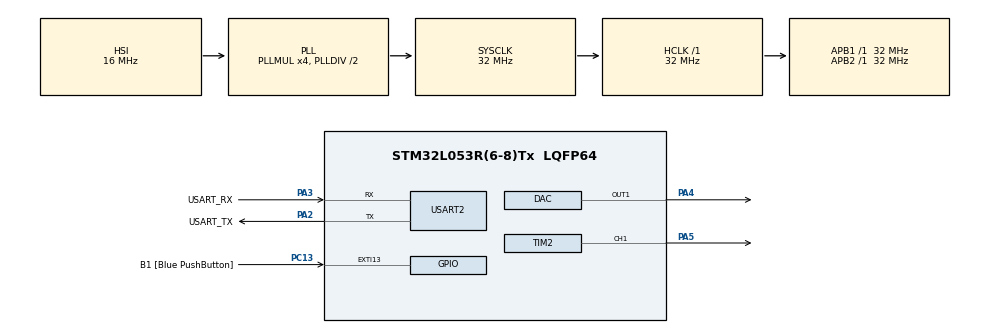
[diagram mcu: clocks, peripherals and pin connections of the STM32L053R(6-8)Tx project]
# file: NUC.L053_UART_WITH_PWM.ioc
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Mcu.Family=STM32L0
Mcu.Name=STM32L053R(6-8)Tx
Mcu.Package=LQFP64
NVIC.USART2_IRQn=true\:0\:0\:false\:false\:true\:true\:true\:true
PA13.GPIO_Label=TMS
PA13.Signal=SYS_SWDIO
PA14.GPIO_Label=TCK
PA14.Signal=SYS_SWCLK
PA2.GPIO_Label=USART_TX
PA2.Mode=Asynchronous
PA2.Signal=USART2_TX
PA3.GPIO_Label=USART_RX
PA3.Mode=Asynchronous
PA3.Signal=USART2_RX
PA4.Signal=COMP_DAC1_group
PA5.Signal=S_TIM2_CH1
PC13.GPIO_Label=B1 [Blue PushButton]
PC13.GPIO_ModeDefaultEXTI=GPIO_MODE_IT_FALLING
PC13.Signal=GPXTI13
PC14-OSC32_IN.Signal=RCC_OSC32_IN
PC15-OSC32_OUT.Signal=RCC_OSC32_OUT
PH0-OSC_IN.Signal=RCC_OSC_IN
PH1-OSC_OUT.Signal=RCC_OSC_OUT
ProjectManager.HeapSize=0x200
ProjectManager.StackSize=0x400
ProjectManager.TargetToolchain=STM32CubeIDE
RCC.AHBFreq_Value=32000000
RCC.APB1Freq_Value=32000000
RCC.APB1TimFreq_Value=32000000
RCC.APB2Freq_Value=32000000
RCC.APB2TimFreq_Value=32000000
RCC.HCLKFreq_Value=32000000
RCC.HSE_VALUE=8000000
RCC.HSI16_VALUE=16000000
RCC.HSI48_VALUE=48000000
RCC.HSI_VALUE=16000000
RCC.LSEState=RCC_LSE_ON
RCC.LSE_VALUE=32768
RCC.MSI_VALUE=2097000
RCC.PLLMUL=RCC_PLLMUL_4
RCC.SYSCLKFreq_VALUE=32000000
RCC.SYSCLKSource=RCC_SYSCLKSOURCE_PLLCLK
RCC.VCOOutputFreq_Value=64000000
SH.COMP_DAC1_group.0=DAC_OUT1,DAC_OUT1
SH.S_TIM2_CH1.0=TIM2_CH1,PWM Generation1 CH1
TIM2.Channel-PWM\ Generation1\ CH1=TIM_CHANNEL_1
TIM2.Period=1500
TIM2.Prescaler=15999
USART2.VirtualMode-Asynchronous=VM_ASYNC
board=NUCLEO-L053R8

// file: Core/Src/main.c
/* USER CODE BEGIN Header */
/**
  ******************************************************************************
  * @file           : main.c
  * @brief          : Main program body
  ******************************************************************************
  * @attention
  *
  * Copyright (c) 2023 STMicroelectronics.
  * All rights reserved.
  *
  * This software is licensed under terms that can be found in the LICENSE file
  * in the root directory of this software component.
  * If no LICENSE file comes with this software, it is provided AS-IS.
  *
  ******************************************************************************
  */
/* USER CODE END Header */
#include "main.h"

DAC_HandleTypeDef hdac;

TIM_HandleTypeDef htim2;

UART_HandleTypeDef huart2;

/* USER CODE BEGIN PV */
volatile uint32_t x=0;
uint8_t Receive_Data[10]={0};
uint32_t i=0;
/* USER CODE END PV */

void SystemClock_Config(void);
static void MX_GPIO_Init(void);
static void MX_USART2_UART_Init(void);
static void MX_DAC_Init(void);
static void MX_TIM2_Init(void);
/* USER CODE BEGIN PFP */
void HAL_UART_RxCpltCallback(UART_HandleTypeDef *huart)
{
	x = (100*Receive_Data[0]);
	i=10+i;

  memset(Receive_Data, '\0',10);
  HAL_UART_Receive_IT(&huart2, Receive_Data , 1);

}
/* USER CODE END PFP */

int main(void)
{

  /* MCU Configuration--------------------------------------------------------*/

  /* Reset of all peripherals, Initializes the Flash interface and the Systick. */
  HAL_Init();

  /* Configure the system clock */
  SystemClock_Config();

  /* Initialize all configured peripherals */
  MX_GPIO_Init();
  MX_USART2_UART_Init();
  MX_DAC_Init();
  MX_TIM2_Init();
  /* USER CODE BEGIN 2 */
  HAL_TIM_PWM_Start(&htim2, TIM_CHANNEL_1);
  HAL_UART_Receive_IT(&huart2, Receive_Data, 1);
  HAL_DAC_Start(&hdac, DAC_CHANNEL_1);
  /* USER CODE END 2 */

  /* Infinite loop */
  /* USER CODE BEGIN WHILE */
  while (1)
  {
	  __HAL_TIM_SET_COMPARE(&htim2, TIM_CHANNEL_1, x);

	  if(i>=100000)
		  i=0;

	  //HAL_DAC_SetValue(&hdac, DAC_CHANNEL_1, DAC_ALIGN_12B_R, x);

    /* USER CODE END WHILE */

  }
}

void SystemClock_Config(void)
{
  RCC_OscInitTypeDef RCC_OscInitStruct = {0};
  RCC_ClkInitTypeDef RCC_ClkInitStruct = {0};
  RCC_PeriphCLKInitTypeDef PeriphClkInit = {0};

  /** Configure the main internal regulator output voltage
  */
  __HAL_PWR_VOLTAGESCALING_CONFIG(PWR_REGULATOR_VOLTAGE_SCALE1);

  /** Initializes the RCC Oscillators according to the specified parameters
  * in the RCC_OscInitTypeDef structure.
  */
  RCC_OscInitStruct.OscillatorType = RCC_OSCILLATORTYPE_HSI;
  RCC_OscInitStruct.HSIState = RCC_HSI_ON;
  RCC_OscInitStruct.HSICalibrationValue = RCC_HSICALIBRATION_DEFAULT;
  RCC_OscInitStruct.PLL.PLLState = RCC_PLL_ON;
  RCC_OscInitStruct.PLL.PLLSource = RCC_PLLSOURCE_HSI;
  RCC_OscInitStruct.PLL.PLLMUL = RCC_PLLMUL_4;
  RCC_OscInitStruct.PLL.PLLDIV = RCC_PLLDIV_2;
  if (HAL_RCC_OscConfig(&RCC_OscInitStruct) != HAL_OK)
  {
    Error_Handler();
  }

  /** Initializes the CPU, AHB and APB buses clocks
  */
  RCC_ClkInitStruct.ClockType = RCC_CLOCKTYPE_HCLK|RCC_CLOCKTYPE_SYSCLK
                              |RCC_CLOCKTYPE_PCLK1|RCC_CLOCKTYPE_PCLK2;
  RCC_ClkInitStruct.SYSCLKSource = RCC_SYSCLKSOURCE_PLLCLK;
  RCC_ClkInitStruct.AHBCLKDivider = RCC_SYSCLK_DIV1;
  RCC_ClkInitStruct.APB1CLKDivider = RCC_HCLK_DIV1;
  RCC_ClkInitStruct.APB2CLKDivider = RCC_HCLK_DIV1;

  if (HAL_RCC_ClockConfig(&RCC_ClkInitStruct, FLASH_LATENCY_1) != HAL_OK)
  {
    Error_Handler();
  }
  PeriphClkInit.PeriphClockSelection = RCC_PERIPHCLK_USART2;
  PeriphClkInit.Usart2ClockSelection = RCC_USART2CLKSOURCE_PCLK1;
  if (HAL_RCCEx_PeriphCLKConfig(&PeriphClkInit) != HAL_OK)
  {
    Error_Handler();
  }
}

static void MX_DAC_Init(void)
{

  DAC_ChannelConfTypeDef sConfig = {0};

  /** DAC Initialization
  */
  hdac.Instance = DAC;
  if (HAL_DAC_Init(&hdac) != HAL_OK)
  {
    Error_Handler();
  }

  /** DAC channel OUT1 config
  */
  sConfig.DAC_Trigger = DAC_TRIGGER_NONE;
  sConfig.DAC_OutputBuffer = DAC_OUTPUTBUFFER_ENABLE;
  if (HAL_DAC_ConfigChannel(&hdac, &sConfig, DAC_CHANNEL_1) != HAL_OK)
  {
    Error_Handler();
  }

}

static void MX_TIM2_Init(void)
{

  TIM_MasterConfigTypeDef sMasterConfig = {0};
  TIM_OC_InitTypeDef sConfigOC = {0};

  htim2.Instance = TIM2;
  htim2.Init.Prescaler = 15999;
  htim2.Init.CounterMode = TIM_COUNTERMODE_UP;
  htim2.Init.Period = 1500;
  htim2.Init.ClockDivision = TIM_CLOCKDIVISION_DIV1;
  htim2.Init.AutoReloadPreload = TIM_AUTORELOAD_PRELOAD_DISABLE;
  if (HAL_TIM_PWM_Init(&htim2) != HAL_OK)
  {
    Error_Handler();
  }
  sMasterConfig.MasterOutputTrigger = TIM_TRGO_RESET;
  sMasterConfig.MasterSlaveMode = TIM_MASTERSLAVEMODE_DISABLE;
  if (HAL_TIMEx_MasterConfigSynchronization(&htim2, &sMasterConfig) != HAL_OK)
  {
    Error_Handler();
  }
  sConfigOC.OCMode = TIM_OCMODE_PWM1;
  sConfigOC.Pulse = 0;
  sConfigOC.OCPolarity = TIM_OCPOLARITY_HIGH;
  sConfigOC.OCFastMode = TIM_OCFAST_DISABLE;
  if (HAL_TIM_PWM_ConfigChannel(&htim2, &sConfigOC, TIM_CHANNEL_1) != HAL_OK)
  {
    Error_Handler();
  }
  HAL_TIM_MspPostInit(&htim2);

}

static void MX_USART2_UART_Init(void)
{

  huart2.Instance = USART2;
  huart2.Init.BaudRate = 115200;
  huart2.Init.WordLength = UART_WORDLENGTH_8B;
  huart2.Init.StopBits = UART_STOPBITS_1;
  huart2.Init.Parity = UART_PARITY_NONE;
  huart2.Init.Mode = UART_MODE_TX_RX;
  huart2.Init.HwFlowCtl = UART_HWCONTROL_NONE;
  huart2.Init.OverSampling = UART_OVERSAMPLING_16;
  huart2.Init.OneBitSampling = UART_ONE_BIT_SAMPLE_DISABLE;
  huart2.AdvancedInit.AdvFeatureInit = UART_ADVFEATURE_NO_INIT;
  if (HAL_UART_Init(&huart2) != HAL_OK)
  {
    Error_Handler();
  }

}

static void MX_GPIO_Init(void)
{
  GPIO_InitTypeDef GPIO_InitStruct = {0};

  /* GPIO Ports Clock Enable */
  __HAL_RCC_GPIOC_CLK_ENABLE();
  __HAL_RCC_GPIOH_CLK_ENABLE();
  __HAL_RCC_GPIOA_CLK_ENABLE();

  /*Configure GPIO pin : B1_Pin */
  GPIO_InitStruct.Pin = B1_Pin;
  GPIO_InitStruct.Mode = GPIO_MODE_IT_FALLING;
  GPIO_InitStruct.Pull = GPIO_NOPULL;
  HAL_GPIO_Init(B1_GPIO_Port, &GPIO_InitStruct);

}

void Error_Handler(void)
{
  __disable_irq();
  while (1)
  {
  }
}
